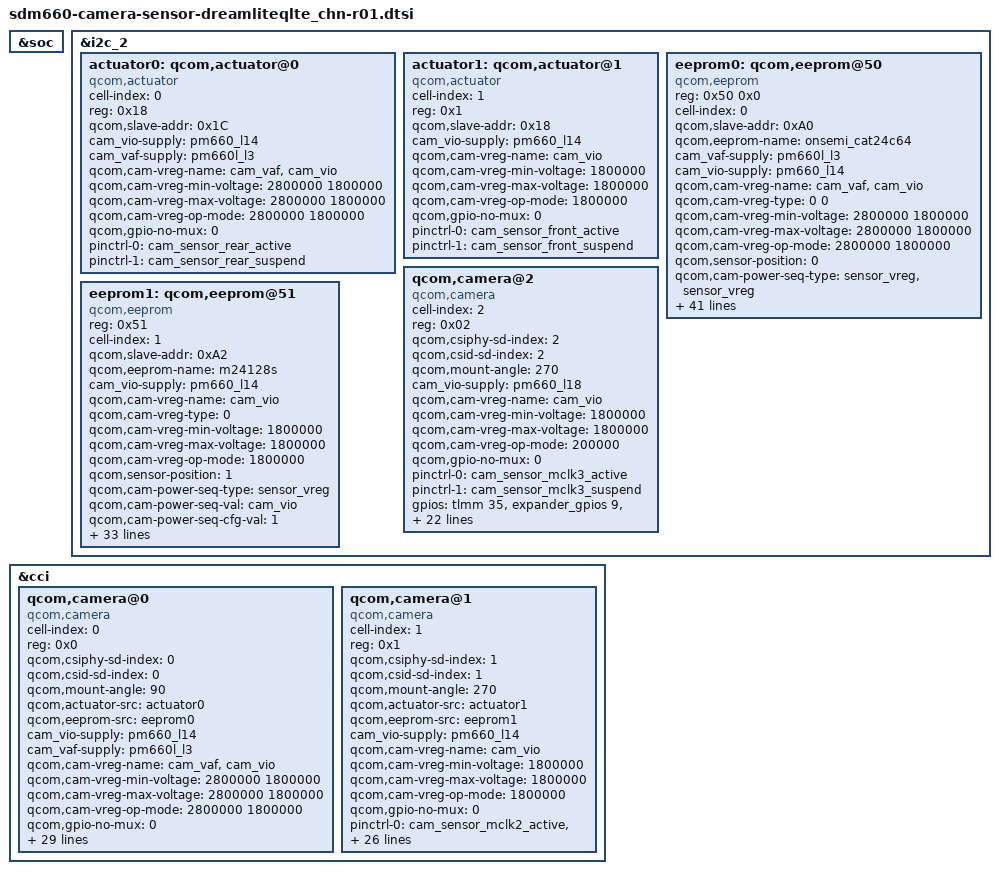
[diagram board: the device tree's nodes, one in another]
/*
 * Copyright (c) 2017, The Linux Foundation. All rights reserved.
 *
 * This program is free software; you can redistribute it and/or modify
 * it under the terms of the GNU General Public License version 2 and
 * only version 2 as published by the Free Software Foundation.
 *
 * This program is distributed in the hope that it will be useful,
 * but WITHOUT ANY WARRANTY; without even the implied warranty of
 * MERCHANTABILITY or FITNESS FOR A PARTICULAR PURPOSE.  See the
 * GNU General Public License for more details.
 */

&soc {
/*	led_flash0: qcom,camera-flash {
		cell-index = <0>;
		compatible = "qcom,camera-flash";
		qcom,flash-type = <3>;
		qcom,cci-master = <0>;
		qcom,flash-name = "sm5705";
	};*/
};

&i2c_2 {
	// Rear Main
	actuator0: qcom,actuator@0 {
		compatible = "qcom,actuator";
		cell-index = <0>;
		reg = <0x18>;
		qcom,slave-addr = <0x1C>;
		cam_vio-supply = <&pm660_l14>;
		cam_vaf-supply = <&pm660l_l3>;
		qcom,cam-vreg-name = "cam_vaf", "cam_vio";
		qcom,cam-vreg-min-voltage = <2800000 1800000>;
		qcom,cam-vreg-max-voltage = <2800000 1800000>;
		qcom,cam-vreg-op-mode = <2800000 1800000>;
		qcom,gpio-no-mux = <0>;

		pinctrl-names = "cam_default", "cam_suspend";
		pinctrl-0 = <&cam_sensor_rear_active>;
		pinctrl-1 = <&cam_sensor_rear_suspend>;
	};
	// Front
	actuator1: qcom,actuator@1 {
		compatible = "qcom,actuator";
		cell-index = <1>;
		reg = <0x1>;
		qcom,slave-addr = <0x18>;
		cam_vio-supply = <&pm660_l14>;
		qcom,cam-vreg-name = "cam_vio";
		qcom,cam-vreg-min-voltage = <1800000>;
		qcom,cam-vreg-max-voltage = <1800000>;
		qcom,cam-vreg-op-mode = <1800000>;
		qcom,gpio-no-mux = <0>;

		pinctrl-names = "cam_default", "cam_suspend";
		pinctrl-0 = <&cam_sensor_front_active>;
		pinctrl-1 = <&cam_sensor_front_suspend>;
	};
	eeprom0: qcom,eeprom@50 {
		compatible = "qcom,eeprom";
		reg = <0x50 0x0>;
		cell-index = <0>;
		qcom,slave-addr = <0xA0>;
		qcom,eeprom-name = "onsemi_cat24c64";
		cam_vaf-supply = <&pm660l_l3>;
		cam_vio-supply = <&pm660_l14>;
		qcom,cam-vreg-name = "cam_vaf", "cam_vio";
		qcom,cam-vreg-type = <0 0>;
		qcom,cam-vreg-min-voltage = <2800000 1800000>;
		qcom,cam-vreg-max-voltage = <2800000 1800000>;
		qcom,cam-vreg-op-mode = <2800000 1800000>;
		qcom,sensor-position = <0>;

		qcom,cam-power-seq-type = "sensor_vreg", "sensor_vreg";
		qcom,cam-power-seq-val = "cam_vaf","cam_vio";
		qcom,cam-power-seq-cfg-val = <1 1>;
		qcom,cam-power-seq-delay = <2 2>;

		qcom,num-blocks = <12>;
		qcom,page0 = <0 0 0 0 0 0>;
		qcom,poll0 = <0 0 0 0 0 0>;
		qcom,mem0 = <0xFC 0x00 2 0 1 0>;

		qcom,page1 = <0 0 0 0 0 0>;
		qcom,poll1 = <0 0 0 0 0 0>;
		qcom,mem1 = <0x4 0xFC 2 0 1 0>;

		qcom,page2 = <0 0 0 0 0 0>;
		qcom,poll2 = <0 0 0 0 0 0>;
		qcom,mem2 = <0x7B8 0x100 2 0 1 0>;

		qcom,page3 = <0 0 0 0 0 0>;
		qcom,poll3 = <0 0 0 0 0 0>;
		qcom,mem3 = <0x4 0x8FC 2 0 1 0>;

		qcom,page4 = <0 0 0 0 0 0>;
		qcom,poll4 = <0 0 0 0 0 0>;
		qcom,mem4 = <0x20 0x900 2 0 1 0>;

		qcom,page5 = <0 0 0 0 0 0>;
		qcom,poll5 = <0 0 0 0 0 0>;
		qcom,mem5 = <0x4 0x9FC 2 0 1 0>;

		qcom,page6 = <0 0 0 0 0 0>;
		qcom,poll6 = <0 0 0 0 0 0>;
		qcom,mem6 = <0x700 0xA00 2 0 1 0>;

		qcom,page7 = <0 0 0 0 0 0>;
		qcom,poll7 = <0 0 0 0 0 0>;
		qcom,mem7 = <0x4 0x11FC 2 0 1 0>;

		qcom,page8 = <0 0 0 0 0 0>;
		qcom,poll8 = <0 0 0 0 0 0>;
		qcom,mem8 = <0x4FC 0x1200 2 0 1 0>;

		qcom,page9 = <0 0 0 0 0 0>;
		qcom,poll9 = <0 0 0 0 0 0>;
		qcom,mem9 = <0x4 0x16FC 2 0 1 0>;

		qcom,page10 = <0 0 0 0 0 0>;
		qcom,poll10 = <0 0 0 0 0 0>;
		qcom,mem10 = <0xFC 0x1700 2 0 1 0>;

		qcom,page11 = <0 0 0 0 0 0>;
		qcom,poll11 = <0 0 0 0 0 0>;
		qcom,mem11 = <0x4 0x17FC 2 0 1 0>;

		qcom,total-size = <0x1800>;
	};

	eeprom1: qcom,eeprom@51 {
		compatible = "qcom,eeprom";
	    reg = <0x51>;
	    cell-index = <1>;
		qcom,slave-addr = <0xA2>;
		qcom,eeprom-name = "m24128s";
		cam_vio-supply = <&pm660_l14>;
		qcom,cam-vreg-name = "cam_vio";
		qcom,cam-vreg-type = <0>;
		qcom,cam-vreg-min-voltage = <1800000>;
		qcom,cam-vreg-max-voltage = <1800000>;
		qcom,cam-vreg-op-mode = <1800000>;
		qcom,sensor-position = <1>;
		qcom,cam-power-seq-type = "sensor_vreg";
		qcom,cam-power-seq-val = "cam_vio";
		qcom,cam-power-seq-cfg-val = <1>;
		qcom,cam-power-seq-delay = <2>;

		qcom,num-blocks = <10>;
		qcom,page0 = <0 0 0 0 0 0>;
		qcom,poll0 = <0 0 0 0 0 0>;
		qcom,mem0 = <0xC0 0x00 2 0 1 0>;

		qcom,page1 = <0 0 0 0 0 0>;
		qcom,poll1 = <0 0 0 0 0 0>;
		qcom,mem1 = <0x4 0xFC 2 0 1 0>;

		qcom,page2 = <0 0 0 0 0 0>;
		qcom,poll2 = <0 0 0 0 0 0>;
		qcom,mem2 = <0x50 0x100 2 0 1 0>;

		qcom,page3 = <0 0 0 0 0 0>;
		qcom,poll3 = <0 0 0 0 0 0>;
		qcom,mem3 = <0x4 0x1FC 2 0 1 0>;

		qcom,page4 = <0 0 0 0 0 0>;
		qcom,poll4 = <0 0 0 0 0 0>;
		qcom,mem4 = <0x20 0x200 2 0 1 0>;

		qcom,page5 = <0 0 0 0 0 0>;
		qcom,poll5 = <0 0 0 0 0 0>;
		qcom,mem5 = <0x4 0x2FC 2 0 1 0>;

		qcom,page6 = <0 0 0 0 0 0>;
		qcom,poll6 = <0 0 0 0 0 0>;
		qcom,mem6 = <0x1800 0x300 2 0 1 0>;

		qcom,page7 = <0 0 0 0 0 0>;
		qcom,poll7 = <0 0 0 0 0 0>;
		qcom,mem7 = <0x4 0x1FFC 2 0 1 0>;

		qcom,page8 = <0 0 0 0 0 0>;
		qcom,poll8 = <0 0 0 0 0 0>;
		qcom,mem8 = <0x700 0x2000 2 0 1 0>;

		qcom,page9 = <0 0 0 0 0 0>;
		qcom,poll9 = <0 0 0 0 0 0>;
		qcom,mem9 = <0x4 0x3BFC 2 0 1 0>;

		qcom,total-size = <0x3C00>;
	};
};

&cci {
	qcom,camera@0 {
		// Rear Main Camera
		cell-index = <0>;
		compatible = "qcom,camera";
		reg = <0x0>;
		qcom,csiphy-sd-index = <0>;
		qcom,csid-sd-index = <0>;
		qcom,mount-angle = <90>;
		qcom,actuator-src = <&actuator0>;
		/*qcom,led-flash-src = <&led_flash0>;*/
		qcom,eeprom-src = <&eeprom0>;
		cam_vio-supply = <&pm660_l14>;
		cam_vaf-supply = <&pm660l_l3>;
		qcom,cam-vreg-name = "cam_vaf", "cam_vio";
		qcom,cam-vreg-min-voltage = <2800000 1800000>;
		qcom,cam-vreg-max-voltage = <2800000 1800000>;
		qcom,cam-vreg-op-mode = <2800000 1800000>;
		qcom,gpio-no-mux = <0>;

		pinctrl-names = "cam_default", "cam_suspend";
		pinctrl-0 = <&cam_sensor_mclk0_active &cam_sensor_rear_active>;
		pinctrl-1 = <&cam_sensor_mclk0_suspend &cam_sensor_rear_suspend>;
		gpios = <&tlmm 32 0>,
			<&tlmm 46 0>,
			<&expander_gpios 16 0>,
			<&expander_gpios 18 0>;
		qcom,gpio-reset = <1>;
		qcom,gpio-vana = <2>;
		qcom,gpio-vdig = <3>;
		qcom,gpio-req-tbl-num = <0 1 2 3>;
		qcom,gpio-req-tbl-flags = <1 0 0 0>;
		qcom,gpio-req-tbl-label = "CAMIF_MCLK0", "CAM_RESET0", "CAM_VANA", "CAM_VDIG";
		qcom,sensor-position = <0>;
		qcom,sensor-mode = <0>;
		qcom,cci-master = <1>;
		status = "ok";
		clocks = <&clock_mmss MCLK0_CLK_SRC>,
			<&clock_mmss MMSS_CAMSS_MCLK0_CLK>;
		clock-names = "cam_src_clk", "cam_clk";
		qcom,clock-rates = <24000000 0>;
		cam,isp = <0>;                  // 0 : INT , 1 : EXT , 2 : SOC
		cam,cal_memory = <2>;           // 0 : N , 1 : FROM , 2 : EEPROM , 3 : OTP
		cam,read_version = <0>;         // 0 : SYSFS , 1 : CAMON
		cam,core_voltage = <0>;         // 0 : N , 1 : Y
		cam,upgrade = <0>;              // 0 : N , 1 : SYSFS , 2 : CAMON
		cam,fw_write = <0>;             // 0 : N , 1 : OS , 2 : SD , 3 : ALL
		cam,fw_dump = <0>;              // 0 : N , 1 : Y
		cam,companion_chip = <0>;       // 0 : N , 1 : Y
		cam,ois = <0>;                  // 0 : N , 1 : Y
		cam,valid = <1>;                // 0 : N , 1 : Y
	};
	qcom,camera@1 {
		// Front Camera
		cell-index = <1>;
		compatible = "qcom,camera";
		reg = <0x1>;
		qcom,csiphy-sd-index = <1>;
		qcom,csid-sd-index = <1>;
		qcom,mount-angle = <270>;
		qcom,actuator-src = <&actuator1>;
		qcom,eeprom-src = <&eeprom1>;
		cam_vio-supply = <&pm660_l14>;
		qcom,cam-vreg-name = "cam_vio";
		qcom,cam-vreg-min-voltage = <1800000>;
		qcom,cam-vreg-max-voltage = <1800000>;
		qcom,cam-vreg-op-mode = <1800000>;
		qcom,gpio-no-mux = <0>;

		pinctrl-names = "cam_default", "cam_suspend";
		pinctrl-0 = <&cam_sensor_mclk2_active &cam_sensor_front_active>;
		pinctrl-1 = <&cam_sensor_mclk2_suspend &cam_sensor_front_suspend>;
		gpios = <&tlmm 34 0>,
			<&tlmm 47 0>,
			<&expander_gpios 8 0>;
		qcom,gpio-reset = <1>;
		qcom,gpio-vana = <2>;
		qcom,gpio-req-tbl-num = <0 1 2>;
		qcom,gpio-req-tbl-flags = <1 0 0>;
		qcom,gpio-req-tbl-label = "CAMIF_MCLK1", "CAM_RESET1", "CAM_VANA";
		qcom,sensor-position = <1>;
		qcom,sensor-mode = <0>;
		qcom,cci-master = <0>;
		status = "ok";
		clocks = <&clock_mmss MCLK2_CLK_SRC>,
			<&clock_mmss MMSS_CAMSS_MCLK2_CLK>;
		clock-names = "cam_src_clk", "cam_clk";
		qcom,clock-rates = <24000000 0>;
		cam,isp = <0>;                  // 0 : INT , 1 : EXT , 2 : SOC
		cam,cal_memory = <2>;           // 0 : N , 1 : FROM , 2 : EEPROM , 3 : OTP
		cam,read_version = <0>;         // 0 : SYSFS , 1 : CAMON
		cam,core_voltage = <0>;         // 0 : N , 1 : Y
		cam,upgrade = <0>;              // 0 : N , 1 : SYSFS , 2 : CAMON
		cam,fw_write = <0>;             // 0 : N , 1 : OS , 2 : SD , 3 : ALL
		cam,fw_dump = <0>;              // 0 : N , 1 : Y
		cam,companion_chip = <0>;       // 0 : N , 1 : Y
		cam,ois = <0>;                  // 0 : N , 1 : Y
		cam,valid = <1>;                // 0 : N , 1 : Y
	};
};

&i2c_2 {
	qcom,camera@2 {
		cell-index = <2>;
		compatible = "qcom,camera";
		reg = <0x02>;
		qcom,csiphy-sd-index = <2>;
		qcom,csid-sd-index = <2>;
		qcom,mount-angle = <270>;
		/* qcom,led-flash-src = <&led_flash0>; */
		/* qcom,secure = <1>; */
		cam_vio-supply = <&pm660_l18>; /* VDD_IRIS_1P8 */
		qcom,cam-vreg-name = "cam_vio";
		qcom,cam-vreg-min-voltage = <1800000>;
		qcom,cam-vreg-max-voltage = <1800000>;
		qcom,cam-vreg-op-mode = <200000>;
		qcom,gpio-no-mux = <0>;
		pinctrl-names = "cam_default", "cam_suspend";
		pinctrl-0 = <&cam_sensor_mclk3_active>;
		pinctrl-1 = <&cam_sensor_mclk3_suspend>;
		gpios = <&tlmm 35 0>,
			<&expander_gpios 9 0>, /* VDD_IRIS_2P8 */
			<&expander_gpios 15 0>; /* VDD_IRIS_1P2 */
		qcom,gpio-vana = <1>;
		qcom,gpio-vdig = <2>;
		qcom,gpio-req-tbl-num = <0 1 2>;
		qcom,gpio-req-tbl-flags = <1 0 0>;
		qcom,gpio-req-tbl-label = "CAMIF_MCLK3",
					"CAM_VANA",
					"CAM_VDIG";
		qcom,sensor-position = <1>;
		qcom,sensor-mode = <0>;
		/* qcom,cci-master = <1>; */
		status = "ok";
		clocks = <&clock_mmss MCLK3_CLK_SRC>,
			<&clock_mmss MMSS_CAMSS_MCLK3_CLK>;
		clock-names = "cam_src_clk", "cam_clk";
		qcom,clock-rates = <24000000 0>;
		cam,isp = <2>;                  // 0 : INT , 1 : EXT , 2 : SOC
		cam,cal_memory = <0>;           // 0 : N , 1 : FROM , 2 : EEPROM , 3 : OTP
		cam,read_version = <0>;         // 0 : SYSFS , 1 : CAMON
		cam,core_voltage = <0>;         // 0 : N , 1 : Y
		cam,upgrade = <0>;              // 0 : N , 1 : SYSFS , 2 : CAMON
		cam,fw_write = <0>;             // 0 : N , 1 : OS , 2 : SD , 3 : ALL
		cam,fw_dump = <0>;              // 0 : N , 1 : Y
		cam,companion_chip = <0>;       // 0 : N , 1 : Y
		cam,ois = <0>;                  // 0 : N , 1 : Y
		cam,valid = <1>;                // 0 : N , 1 : Y
	};
};
